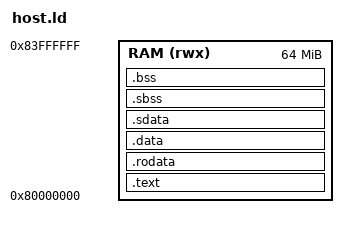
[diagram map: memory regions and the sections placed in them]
/* Generated by pipeline/gen_system_header.py from targets/hetero/system.py.
 * Do not edit: change the machine model and regenerate.
 */
OUTPUT_ARCH(riscv)
ENTRY(_start)

MEMORY
{
  RAM (rwx) : ORIGIN = 0x80000000, LENGTH = 0x04000000
}

SECTIONS
{
  .text : {
    KEEP(*(.text.init))
    *(.text*)
  } > RAM

  .rodata : { *(.rodata*) *(.srodata*) } > RAM

  . = ALIGN(8);
  .data : { *(.data*) } > RAM

  . = ALIGN(8);
  __global_pointer$ = . + 0x800;
  .sdata : { *(.sdata*) } > RAM

  /* LMA == VMA, so crt0 skips the copy loop. */
  __data_start = 0;
  __data_end = 0;
  __data_load_start = 0;

  . = ALIGN(8);
  __bss_start = .;
  .sbss : { *(.sbss*) } > RAM
  .bss  : { *(.bss*) *(COMMON) } > RAM
  . = ALIGN(8);
  __bss_end = .;

  /* Heap and stack: symbols only, so no zero-filled program header. */
  . = ALIGN(16);
  __heap_start = .;
  __heap_end = __heap_start + 0x800000;
  __stack_top = __heap_end + 0x40000;

  ASSERT(__stack_top <= ORIGIN(RAM) + LENGTH(RAM),
         "host image overflows its window in main memory")
}
